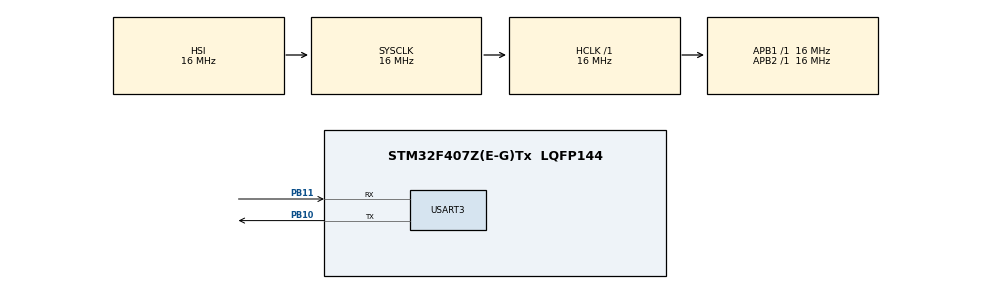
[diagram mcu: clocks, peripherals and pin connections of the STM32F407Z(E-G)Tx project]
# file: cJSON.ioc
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Mcu.Family=STM32F4
Mcu.Name=STM32F407Z(E-G)Tx
Mcu.Package=LQFP144
NVIC.PriorityGroup=NVIC_PRIORITYGROUP_4
NVIC.TIM1_UP_TIM10_IRQn=true\:15\:0\:false\:false\:true\:false\:true\:true
NVIC.TimeBase=TIM1_UP_TIM10_IRQn
NVIC.TimeBaseIP=TIM1
PA13.Mode=JTAG_4_pins
PA13.Signal=SYS_JTMS-SWDIO
PA14.Mode=JTAG_4_pins
PA14.Signal=SYS_JTCK-SWCLK
PA15.Mode=JTAG_4_pins
PA15.Signal=SYS_JTDI
PB10.Mode=Asynchronous
PB10.Signal=USART3_TX
PB11.Mode=Asynchronous
PB11.Signal=USART3_RX
PB3.Mode=JTAG_4_pins
PB3.Signal=SYS_JTDO-SWO
PH0-OSC_IN.Mode=HSE-External-Clock-Source
PH0-OSC_IN.Signal=RCC_OSC_IN
PH1-OSC_OUT.Mode=HSE-External-Clock-Source
PH1-OSC_OUT.Signal=RCC_OSC_OUT
ProjectManager.HeapSize=0x200
ProjectManager.StackSize=0x400
ProjectManager.TargetToolchain=STM32CubeIDE
RCC.AHBFreq_Value=16000000
RCC.APB1Freq_Value=16000000
RCC.APB2Freq_Value=16000000
RCC.CortexFreq_Value=16000000
RCC.HSE_VALUE=25000000
RCC.HSI_VALUE=16000000
RCC.LSE_VALUE=32768
RCC.SYSCLKFreq_VALUE=16000000
RCC.VCOOutputFreq_Value=192000000
USART3.VirtualMode=VM_ASYNC
VP_SYS_VS_tim1.Mode=TIM1
board=custom

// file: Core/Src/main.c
/* USER CODE BEGIN Header */
/**
  ******************************************************************************
  * @file           : main.c
  * @brief          : Main program body
  ******************************************************************************
  * @attention
  *
  * Copyright (c) 2024 STMicroelectronics.
  * All rights reserved.
  *
  * This software is licensed under terms that can be found in the LICENSE file
  * in the root directory of this software component.
  * If no LICENSE file comes with this software, it is provided AS-IS.
  *
  ******************************************************************************
  */
/* USER CODE END Header */
#include "main.h"

/* USER CODE BEGIN Includes */
#include <stdio.h>
#include <stdlib.h>
#include <string.h>
#include "cJSON.h"

#define NULL_ERROR NULL

/* USER CODE END Includes */

UART_HandleTypeDef huart3;

/* USER CODE BEGIN PV */
#ifdef __GNUC__
#define PUTCHAR_PROTOTYPE int __io_putchar(int ch)
#else
#define PUTCHAR_PROTOTYPE int fputc(int ch, FILE *f)
#endif

PUTCHAR_PROTOTYPE
{
  HAL_UART_Transmit(&huart3, (uint8_t *)&ch, 1, HAL_MAX_DELAY);
  return ch;
}
/* USER CODE END PV */

void SystemClock_Config(void);
static void MX_GPIO_Init(void);
static void MX_USART3_UART_Init(void);

/* USER CODE BEGIN 0 */

static char* Serilize(int Temp, int GatPos[3])
{
    const unsigned int Positions[3] = {2,5,10};
    char *string = NULL;
    cJSON *name = NULL;
    cJSON *resolutions = NULL;
    cJSON *resolution = NULL;
    cJSON *width = NULL;
    cJSON *height = NULL;
    size_t index = 0;

    cJSON *monitor = cJSON_CreateObject();
    if (monitor == NULL)
    {
        cJSON_Delete(monitor);
        return NULL_ERROR;
    }

    name = cJSON_CreateString("Gantry");
    if (name == NULL)
    {
        cJSON_Delete(monitor);
        return NULL_ERROR;
    }
    cJSON_AddItemToObject(monitor, "Name", name);

    cJSON_AddNumberToObject(monitor, "Temperature", Temp);

    resolutions = cJSON_CreateArray();
    if (resolutions == NULL)
    {
        cJSON_Delete(monitor);
         return NULL_ERROR;
    }
    cJSON_AddItemToObject(monitor, "GantryPositions", resolutions);

        resolution = cJSON_CreateObject();
        if (resolution == NULL)
        {
            cJSON_Delete(monitor);
         return NULL_ERROR;
        }
        cJSON_AddItemToArray(resolutions, resolution);

        width = cJSON_CreateNumber(Positions[0]);
        if (width == NULL)
        {
            cJSON_Delete(monitor);
         return NULL_ERROR;
        }
        cJSON_AddItemToObject(resolution, "X-Position", width);

        height = cJSON_CreateNumber(Positions[1]);
        if (height == NULL)
        {
            cJSON_Delete(monitor);
         return NULL_ERROR;
        }
        cJSON_AddItemToObject(resolution, "Y-Position", height);

        height = cJSON_CreateNumber(Positions[2]);
        if (height == NULL)
        {
            cJSON_Delete(monitor);
         return NULL_ERROR;
        }
        cJSON_AddItemToObject(resolution, "Z-Position", height);

    string = cJSON_Print(monitor);
    if (string == NULL)
    {
        fprintf(stderr, "Failed to print monitor.\n");
    }

    return string;
}

static int DeSerilize(const char * const monitor)
{
    const cJSON *resolution = NULL;
    const cJSON *resolutions = NULL;
    int status = 0;
    cJSON *monitor_json = cJSON_Parse(monitor);
    if (monitor_json == NULL)
    {
        const char *error_ptr = cJSON_GetErrorPtr();
        if (error_ptr != NULL)
        {
            fprintf(stderr, "Error before: %s\n", error_ptr);
        }
        status = 0;
         return 0;
    }

    cJSON *gantry = cJSON_GetObjectItemCaseSensitive(monitor_json, "Gantry");
    if (cJSON_IsString(gantry) && (gantry->valuestring != NULL))
    {
        printf("Checking monitor \"%s\"\n", gantry->valuestring);
    }
    else
    {
        fprintf(stderr, "Error: Gantry name is not a valid string.\n");
        status = 0;
        // return 0;
    }

    cJSON *temperature = cJSON_GetObjectItemCaseSensitive(monitor_json, "Temperature");
    if (cJSON_IsNumber(temperature))
    {
        printf("Temperature is %f\n", temperature->valuedouble);
    }
    else
    {
        fprintf(stderr, "Error: Temperature is not a valid number.\n");
        status = 0;
        // return 0;
    }

    resolutions = cJSON_GetObjectItemCaseSensitive(monitor_json, "GantryPositions");
    cJSON_ArrayForEach(resolution, resolutions)
    {
        cJSON *x = cJSON_GetObjectItemCaseSensitive(resolution, "Y-Position");
        cJSON *y = cJSON_GetObjectItemCaseSensitive(resolution, "X-Position");
        cJSON *z = cJSON_GetObjectItemCaseSensitive(resolution, "Z-Position");

            printf("The X - position of the Gantry is %f\n",x->valuedouble);
            printf("The Y - position of the Gantry is %f\n",y->valuedouble);
            printf("The Z - position of the Gantry is %f\n",z->valuedouble);
    }
    return 1;

}

/* USER CODE END 0 */

int main(void)
{

  /* MCU Configuration--------------------------------------------------------*/

  /* Reset of all peripherals, Initializes the Flash interface and the Systick. */
  HAL_Init();

  /* Configure the system clock */
  SystemClock_Config();

  /* Initialize all configured peripherals */
  MX_GPIO_Init();
  MX_USART3_UART_Init();

  /* Infinite loop */
  while (1)
  {

    /* USER CODE BEGIN 3 */

	  int gatPos[] = {31,23,24};
	      char *monitor_json = Serilize(23, gatPos);
	      if (monitor_json == NULL)
	      {
	          fprintf(stderr, "Failed to create monitor JSON.\n");
	          return EXIT_FAILURE;
	      }

	      printf("Created Monitor JSON:\n%s\n", monitor_json);

	      if (DeSerilize(monitor_json))
	      {
	          printf("Success\n");
	      }
	      else
	      {
	          printf("Fail\n");
	      }

	      free(monitor_json);
  }
  /* USER CODE END 3 */
}

void SystemClock_Config(void)
{
  RCC_OscInitTypeDef RCC_OscInitStruct = {0};
  RCC_ClkInitTypeDef RCC_ClkInitStruct = {0};

  /** Configure the main internal regulator output voltage
  */
  __HAL_RCC_PWR_CLK_ENABLE();
  __HAL_PWR_VOLTAGESCALING_CONFIG(PWR_REGULATOR_VOLTAGE_SCALE1);

  /** Initializes the RCC Oscillators according to the specified parameters
  * in the RCC_OscInitTypeDef structure.
  */
  RCC_OscInitStruct.OscillatorType = RCC_OSCILLATORTYPE_HSI;
  RCC_OscInitStruct.HSIState = RCC_HSI_ON;
  RCC_OscInitStruct.HSICalibrationValue = RCC_HSICALIBRATION_DEFAULT;
  RCC_OscInitStruct.PLL.PLLState = RCC_PLL_NONE;
  if (HAL_RCC_OscConfig(&RCC_OscInitStruct) != HAL_OK)
  {
    Error_Handler();
  }

  /** Initializes the CPU, AHB and APB buses clocks
  */
  RCC_ClkInitStruct.ClockType = RCC_CLOCKTYPE_HCLK|RCC_CLOCKTYPE_SYSCLK
                              |RCC_CLOCKTYPE_PCLK1|RCC_CLOCKTYPE_PCLK2;
  RCC_ClkInitStruct.SYSCLKSource = RCC_SYSCLKSOURCE_HSI;
  RCC_ClkInitStruct.AHBCLKDivider = RCC_SYSCLK_DIV1;
  RCC_ClkInitStruct.APB1CLKDivider = RCC_HCLK_DIV1;
  RCC_ClkInitStruct.APB2CLKDivider = RCC_HCLK_DIV1;

  if (HAL_RCC_ClockConfig(&RCC_ClkInitStruct, FLASH_LATENCY_0) != HAL_OK)
  {
    Error_Handler();
  }
}

static void MX_USART3_UART_Init(void)
{

  huart3.Instance = USART3;
  huart3.Init.BaudRate = 115200;
  huart3.Init.WordLength = UART_WORDLENGTH_8B;
  huart3.Init.StopBits = UART_STOPBITS_1;
  huart3.Init.Parity = UART_PARITY_NONE;
  huart3.Init.Mode = UART_MODE_TX_RX;
  huart3.Init.HwFlowCtl = UART_HWCONTROL_NONE;
  huart3.Init.OverSampling = UART_OVERSAMPLING_16;
  if (HAL_UART_Init(&huart3) != HAL_OK)
  {
    Error_Handler();
  }

}

static void MX_GPIO_Init(void)
{

  /* GPIO Ports Clock Enable */
  __HAL_RCC_GPIOH_CLK_ENABLE();
  __HAL_RCC_GPIOB_CLK_ENABLE();
  __HAL_RCC_GPIOA_CLK_ENABLE();

}

void HAL_TIM_PeriodElapsedCallback(TIM_HandleTypeDef *htim)
{
  if (htim->Instance == TIM1) {
    HAL_IncTick();
  }
}

void Error_Handler(void)
{
  __disable_irq();
  while (1)
  {
  }
}
